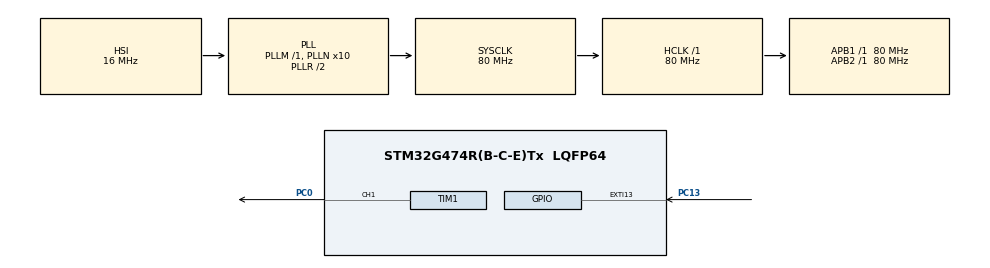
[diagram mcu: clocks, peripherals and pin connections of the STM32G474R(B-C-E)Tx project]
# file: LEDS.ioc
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Dma.Request0=TIM1_CH1
Dma.TIM1_CH1.0.Direction=DMA_MEMORY_TO_PERIPH
Dma.TIM1_CH1.0.EventEnable=DISABLE
Dma.TIM1_CH1.0.Instance=DMA1_Channel1
Dma.TIM1_CH1.0.MemDataAlignment=DMA_MDATAALIGN_BYTE
Dma.TIM1_CH1.0.MemInc=DMA_MINC_ENABLE
Dma.TIM1_CH1.0.Mode=DMA_NORMAL
Dma.TIM1_CH1.0.PeriphDataAlignment=DMA_PDATAALIGN_HALFWORD
Dma.TIM1_CH1.0.PeriphInc=DMA_PINC_DISABLE
Dma.TIM1_CH1.0.Polarity=HAL_DMAMUX_REQ_GEN_RISING
Dma.TIM1_CH1.0.Priority=DMA_PRIORITY_LOW
Dma.TIM1_CH1.0.RequestNumber=1
Dma.TIM1_CH1.0.SignalID=NONE
Dma.TIM1_CH1.0.SyncEnable=DISABLE
Dma.TIM1_CH1.0.SyncPolarity=HAL_DMAMUX_SYNC_NO_EVENT
Dma.TIM1_CH1.0.SyncRequestNumber=1
Dma.TIM1_CH1.0.SyncSignalID=NONE
Mcu.Family=STM32G4
Mcu.Name=STM32G474R(B-C-E)Tx
Mcu.Package=LQFP64
NUCLEO-G474RE.BUTTON=1
NUCLEO-G474RE.LD2=false
NUCLEO-G474RE.VCP=true
NVIC.DMA1_Channel1_IRQn=true\:0\:0\:false\:false\:true\:false\:true\:true
NVIC.EXTI15_10_IRQn=true\:0\:0\:false\:false\:true\:false\:true\:true
NVIC.PriorityGroup=NVIC_PRIORITYGROUP_4
PA13.GPIO_Label=T_SWDIO
PA13.Mode=Serial_Wire
PA13.Signal=SYS_JTMS-SWDIO
PA14.GPIO_Label=T_SWCLK
PA14.Mode=Serial_Wire
PA14.Signal=SYS_JTCK-SWCLK
PB3.GPIO_Label=T_SWO
PB3.Signal=SYS_JTDO-SWO
PC0.Signal=S_TIM1_CH1
PC13.Signal=GPXTI13
PC14-OSC32_IN.GPIO_Label=RCC_OSC32_IN
PC14-OSC32_IN.Signal=RCC_OSC32_IN
PC15-OSC32_OUT.GPIO_Label=RCC_OSC32_OUT
PC15-OSC32_OUT.Signal=RCC_OSC32_OUT
PF0-OSC_IN.GPIO_Label=RCC_OSC_IN
PF0-OSC_IN.Signal=RCC_OSC_IN
PF1-OSC_OUT.GPIO_Label=RCC_OSC_OUT
PF1-OSC_OUT.Signal=RCC_OSC_OUT
ProjectManager.HeapSize=0x200
ProjectManager.StackSize=0x400
ProjectManager.TargetToolchain=CMake
RCC.ADC12Freq_Value=80000000
RCC.ADC345Freq_Value=80000000
RCC.AHBFreq_Value=80000000
RCC.APB1Freq_Value=80000000
RCC.APB1TimFreq_Value=80000000
RCC.APB2Freq_Value=80000000
RCC.APB2TimFreq_Value=80000000
RCC.CortexFreq_Value=80000000
RCC.EXTERNAL_CLOCK_VALUE=12288000
RCC.HCLKFreq_Value=80000000
RCC.HSE_VALUE=24000000
RCC.HSI48_VALUE=48000000
RCC.HSI_VALUE=16000000
RCC.LSE_VALUE=32768
RCC.PLLN=10
RCC.RTCClockSelection=RCC_RTCCLKSOURCE_LSE
RCC.SYSCLKFreq_VALUE=80000000
RCC.SYSCLKSource=RCC_SYSCLKSOURCE_PLLCLK
RCC.USBFreq_Value=80000000
RCC.VCOOutputFreq_Value=160000000
SH.S_TIM1_CH1.0=TIM1_CH1,PWM Generation1 CH1
TIM1.Channel-PWM\ Generation1\ CH1=TIM_CHANNEL_1
TIM1.PeriodNoDither=100-1
VP_NUCLEO-G474RE_VS_BSP_COMMON.Mode=COMMON
VP_SYS_VS_DBSignals.Mode=DisableDeadBatterySignals
VP_TIM1_VS_ClockSourceINT.Mode=Internal
board=NUCLEO-G474RE

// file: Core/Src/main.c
/* USER CODE BEGIN Header */
/**
  ******************************************************************************
  * @file           : main.c
  * @brief          : Main program body
  ******************************************************************************
  * @attention
  *
  * Copyright (c) 2026 STMicroelectronics.
  * All rights reserved.
  *
  * This software is licensed under terms that can be found in the LICENSE file
  * in the root directory of this software component.
  * If no LICENSE file comes with this software, it is provided AS-IS.
  *
  ******************************************************************************
  */
/* USER CODE END Header */
#include "main.h"

/* USER CODE BEGIN Includes */
#include "ws2812b.h"

/* USER CODE END Includes */

/* USER CODE BEGIN PTD */

typedef enum
{
    STATE_RED,
    STATE_GREEN,
    STATE_BLUE
} LedState;

/* USER CODE END PTD */

/* USER CODE BEGIN PD */
#define LED_COUNT 5U // Liczba diód
#define PERIOD_MS 3000U // Okres zmian kolorów
#define FRAME_MS  10U // Częstotliwość nadpisywania diód

#define BLINK_MS 500U // Długość jednego cyklu diody ( w 3 s zielona dioda rozświetli się 6 razy)
/* USER CODE END PD */

COM_InitTypeDef BspCOMInit;
TIM_HandleTypeDef htim1;
DMA_HandleTypeDef hdma_tim1_ch1;

void SystemClock_Config(void);
static void MX_GPIO_Init(void);
static void MX_DMA_Init(void);
static void MX_TIM1_Init(void);

/* USER CODE BEGIN 0 */

//volatile uint32_t debug_now = 0U;
//volatile uint32_t debug_elapsed = 0U;
//volatile uint32_t debug_state_start = 0U;

volatile uint8_t r = 0;
volatile uint8_t g = 0;
volatile uint8_t b = 0;

volatile uint8_t button_event = 0U;

static LedState state = STATE_RED;
static uint32_t state_start = 0U;
static uint32_t last_frame = 0U;

/* USER CODE END 0 */

int main(void)
{

  /* MCU Configuration--------------------------------------------------------*/

  /* Reset of all peripherals, Initializes the Flash interface and the Systick. */
  HAL_Init();

  /* Configure the system clock */
  SystemClock_Config();

  /* Initialize all configured peripherals */
  MX_GPIO_Init();
  MX_DMA_Init();
  MX_TIM1_Init();
  /* USER CODE BEGIN 2 */
  ws2812b_init(&htim1);
  /* USER CODE END 2 */

  /* Initialize USER push-button, will be used to trigger an interrupt each time it's pressed.*/
  BSP_PB_Init(BUTTON_USER, BUTTON_MODE_EXTI);

  /* Initialize COM1 port (115200, 8 bits (7-bit data + 1 stop bit), no parity */
  BspCOMInit.BaudRate   = 115200;
  BspCOMInit.WordLength = COM_WORDLENGTH_8B;
  BspCOMInit.StopBits   = COM_STOPBITS_1;
  BspCOMInit.Parity     = COM_PARITY_NONE;
  BspCOMInit.HwFlowCtl  = COM_HWCONTROL_NONE;
  if (BSP_COM_Init(COM1, &BspCOMInit) != BSP_ERROR_NONE)
  {
    Error_Handler();
  }

  /* Infinite loop */
  /* USER CODE BEGIN WHILE */

  uint32_t elapsed = 0U; // Czas od początku okresu zmiany koloru
  uint32_t phase = 0U; // Faza jednego okresu diody

  while (1)
  {
	  uint32_t now = HAL_GetTick();

	  if (button_event != 0U) // Jeżeli przycisk był naciśnięty odpala się niebieska dioda
	  {
		  __disable_irq();
		  button_event = 0U;
		  __enable_irq();

		  if (state != STATE_BLUE)
		  {
			  state = STATE_BLUE;
			  state_start = now;
		  }
	  }

	  switch(state){ // Wybór diody

	  	  case STATE_RED:
	  	  {
	  		 elapsed = now - state_start;
	  		 phase = elapsed % BLINK_MS;

	  		  r = (phase < BLINK_MS / 2U) ? 255 : 0; // Czerwony led jest włączony przez połowę okresu diody
	  		  g = 0U;
	  		  b = 0U;

	  		  if (elapsed >= PERIOD_MS){ // Po 3s zmienia się na zielony
	  			  state = STATE_GREEN;
	  			  state_start = now;
	  		  }

	  		  break;
	  	  }

	  	  case STATE_GREEN:
	  	  {
	  		  elapsed = now - state_start;
			  phase = elapsed % BLINK_MS;

	  		  r = 0;
	  		  g = (uint8_t)((phase * 255U)/BLINK_MS); // Zmienia się w kształt sygnału piłokształtnego
	  		  b = 0;

	  		if (elapsed >= PERIOD_MS) // Po 3s zmienia się z powrotem na czerwony
	  		{
				  state = STATE_RED;
				  state_start = now;
		    }

	  		break;
	  	  }

	  	  case STATE_BLUE:
	  	  {
	  		elapsed = now - state_start;

			if (elapsed < 3000U)
			{
				r = 0U;
				b = ((elapsed / BLINK_MS) % 2U == 0U) ? 255U : 0U; // mignięcie 3 razy
				g = 0U;
			}
			else
			{						// Po mignięciu 3 razy zmienia się na czerwoną diodę
				state = STATE_RED;
				state_start = now;

				r = 255U;
				g = 0U;
				b = 0U;
			}

			break;
	  	  }

	  	  default:
			{
				state = STATE_RED;
				state_start = now;
				break;
			}
	  }

	  if ((uint32_t)(now - last_frame) >= FRAME_MS)  // Jeżeli od ostatniego update'u upłynęło wystarczająco czasu to następuje następny
	      {
	          last_frame = now;

	          ws2812b_wait(&htim1);

	          for (uint32_t i = 0; i < LED_COUNT; i++)
	          {
	              ws2812b_set_color(i,r,g,b);
	          }

	          ws2812b_update(&htim1);
	      }

    /* USER CODE END WHILE */

  }
}

void SystemClock_Config(void)
{
  RCC_OscInitTypeDef RCC_OscInitStruct = {0};
  RCC_ClkInitTypeDef RCC_ClkInitStruct = {0};

  /** Configure the main internal regulator output voltage
  */
  HAL_PWREx_ControlVoltageScaling(PWR_REGULATOR_VOLTAGE_SCALE1);

  /** Initializes the RCC Oscillators according to the specified parameters
  * in the RCC_OscInitTypeDef structure.
  */
  RCC_OscInitStruct.OscillatorType = RCC_OSCILLATORTYPE_HSI;
  RCC_OscInitStruct.HSIState = RCC_HSI_ON;
  RCC_OscInitStruct.HSICalibrationValue = RCC_HSICALIBRATION_DEFAULT;
  RCC_OscInitStruct.PLL.PLLState = RCC_PLL_ON;
  RCC_OscInitStruct.PLL.PLLSource = RCC_PLLSOURCE_HSI;
  RCC_OscInitStruct.PLL.PLLM = RCC_PLLM_DIV1;
  RCC_OscInitStruct.PLL.PLLN = 10;
  RCC_OscInitStruct.PLL.PLLP = RCC_PLLP_DIV2;
  RCC_OscInitStruct.PLL.PLLQ = RCC_PLLQ_DIV2;
  RCC_OscInitStruct.PLL.PLLR = RCC_PLLR_DIV2;
  if (HAL_RCC_OscConfig(&RCC_OscInitStruct) != HAL_OK)
  {
    Error_Handler();
  }

  /** Initializes the CPU, AHB and APB buses clocks
  */
  RCC_ClkInitStruct.ClockType = RCC_CLOCKTYPE_HCLK|RCC_CLOCKTYPE_SYSCLK
                              |RCC_CLOCKTYPE_PCLK1|RCC_CLOCKTYPE_PCLK2;
  RCC_ClkInitStruct.SYSCLKSource = RCC_SYSCLKSOURCE_PLLCLK;
  RCC_ClkInitStruct.AHBCLKDivider = RCC_SYSCLK_DIV1;
  RCC_ClkInitStruct.APB1CLKDivider = RCC_HCLK_DIV1;
  RCC_ClkInitStruct.APB2CLKDivider = RCC_HCLK_DIV1;

  if (HAL_RCC_ClockConfig(&RCC_ClkInitStruct, FLASH_LATENCY_2) != HAL_OK)
  {
    Error_Handler();
  }
}

static void MX_TIM1_Init(void)
{

  TIM_ClockConfigTypeDef sClockSourceConfig = {0};
  TIM_MasterConfigTypeDef sMasterConfig = {0};
  TIM_OC_InitTypeDef sConfigOC = {0};
  TIM_BreakDeadTimeConfigTypeDef sBreakDeadTimeConfig = {0};

  htim1.Instance = TIM1;
  htim1.Init.Prescaler = 0;
  htim1.Init.CounterMode = TIM_COUNTERMODE_UP;
  htim1.Init.Period = 99;
  htim1.Init.ClockDivision = TIM_CLOCKDIVISION_DIV1;
  htim1.Init.RepetitionCounter = 0;
  htim1.Init.AutoReloadPreload = TIM_AUTORELOAD_PRELOAD_DISABLE;
  if (HAL_TIM_Base_Init(&htim1) != HAL_OK)
  {
    Error_Handler();
  }
  sClockSourceConfig.ClockSource = TIM_CLOCKSOURCE_INTERNAL;
  if (HAL_TIM_ConfigClockSource(&htim1, &sClockSourceConfig) != HAL_OK)
  {
    Error_Handler();
  }
  if (HAL_TIM_PWM_Init(&htim1) != HAL_OK)
  {
    Error_Handler();
  }
  sMasterConfig.MasterOutputTrigger = TIM_TRGO_RESET;
  sMasterConfig.MasterOutputTrigger2 = TIM_TRGO2_RESET;
  sMasterConfig.MasterSlaveMode = TIM_MASTERSLAVEMODE_DISABLE;
  if (HAL_TIMEx_MasterConfigSynchronization(&htim1, &sMasterConfig) != HAL_OK)
  {
    Error_Handler();
  }
  sConfigOC.OCMode = TIM_OCMODE_PWM1;
  sConfigOC.Pulse = 0;
  sConfigOC.OCPolarity = TIM_OCPOLARITY_HIGH;
  sConfigOC.OCNPolarity = TIM_OCNPOLARITY_HIGH;
  sConfigOC.OCFastMode = TIM_OCFAST_DISABLE;
  sConfigOC.OCIdleState = TIM_OCIDLESTATE_RESET;
  sConfigOC.OCNIdleState = TIM_OCNIDLESTATE_RESET;
  if (HAL_TIM_PWM_ConfigChannel(&htim1, &sConfigOC, TIM_CHANNEL_1) != HAL_OK)
  {
    Error_Handler();
  }
  sBreakDeadTimeConfig.OffStateRunMode = TIM_OSSR_DISABLE;
  sBreakDeadTimeConfig.OffStateIDLEMode = TIM_OSSI_DISABLE;
  sBreakDeadTimeConfig.LockLevel = TIM_LOCKLEVEL_OFF;
  sBreakDeadTimeConfig.DeadTime = 0;
  sBreakDeadTimeConfig.BreakState = TIM_BREAK_DISABLE;
  sBreakDeadTimeConfig.BreakPolarity = TIM_BREAKPOLARITY_HIGH;
  sBreakDeadTimeConfig.BreakFilter = 0;
  sBreakDeadTimeConfig.BreakAFMode = TIM_BREAK_AFMODE_INPUT;
  sBreakDeadTimeConfig.Break2State = TIM_BREAK2_DISABLE;
  sBreakDeadTimeConfig.Break2Polarity = TIM_BREAK2POLARITY_HIGH;
  sBreakDeadTimeConfig.Break2Filter = 0;
  sBreakDeadTimeConfig.Break2AFMode = TIM_BREAK_AFMODE_INPUT;
  sBreakDeadTimeConfig.AutomaticOutput = TIM_AUTOMATICOUTPUT_DISABLE;
  if (HAL_TIMEx_ConfigBreakDeadTime(&htim1, &sBreakDeadTimeConfig) != HAL_OK)
  {
    Error_Handler();
  }
  HAL_TIM_MspPostInit(&htim1);

}

static void MX_DMA_Init(void)
{

  /* DMA controller clock enable */
  __HAL_RCC_DMAMUX1_CLK_ENABLE();
  __HAL_RCC_DMA1_CLK_ENABLE();

  /* DMA interrupt init */
  /* DMA1_Channel1_IRQn interrupt configuration */
  HAL_NVIC_SetPriority(DMA1_Channel1_IRQn, 0, 0);
  HAL_NVIC_EnableIRQ(DMA1_Channel1_IRQn);

}

static void MX_GPIO_Init(void)
{

  /* GPIO Ports Clock Enable */
  __HAL_RCC_GPIOC_CLK_ENABLE();
  __HAL_RCC_GPIOF_CLK_ENABLE();
  __HAL_RCC_GPIOA_CLK_ENABLE();
  __HAL_RCC_GPIOB_CLK_ENABLE();

}

/* USER CODE BEGIN 4 */
void HAL_GPIO_EXTI_Callback(uint16_t GPIO_Pin)
{

    if (GPIO_Pin == GPIO_PIN_13)
	{
    	button_event = 1U;
	}
}
/* USER CODE END 4 */

void Error_Handler(void)
{
  __disable_irq();
  while (1)
  {
  }
}
